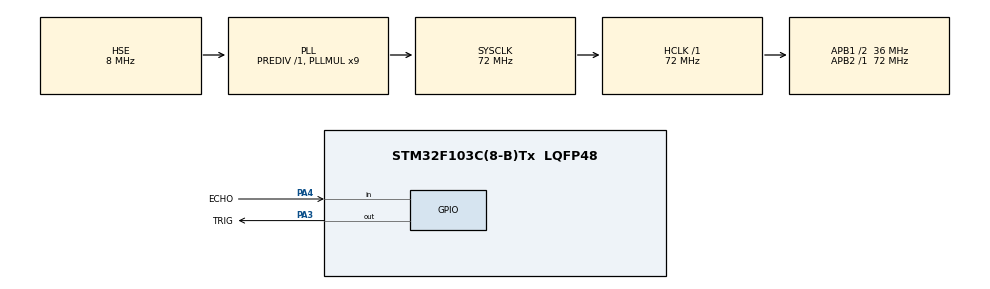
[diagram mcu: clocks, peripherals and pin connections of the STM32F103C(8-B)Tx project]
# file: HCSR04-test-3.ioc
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Mcu.Family=STM32F1
RCC.PLLSourceVirtual=RCC_PLLSOURCE_HSE
PD1-OSC_OUT.Mode=HSE-External-Oscillator
NVIC.TIM1_UP_IRQn=true\:0\:0\:false\:false\:true\:false\:true
PD0-OSC_IN.Signal=RCC_OSC_IN
RCC.APB1CLKDivider=RCC_HCLK_DIV2
RCC.SYSCLKSource=RCC_SYSCLKSOURCE_PLLCLK
ProjectManager.StackSize=0x400
PD1-OSC_OUT.Signal=RCC_OSC_OUT
PA13.Signal=SYS_JTMS-SWDIO
ProjectManager.TargetToolchain=STM32CubeIDE
RCC.HCLKFreq_Value=72000000
RCC.APB2TimFreq_Value=72000000
RCC.USBFreq_Value=72000000
RCC.AHBFreq_Value=72000000
PD0-OSC_IN.Mode=HSE-External-Oscillator
board=custom
RCC.PLLMUL=RCC_PLL_MUL9
RCC.APB2Freq_Value=72000000
VP_TIM2_VS_ClockSourceINT.Mode=Internal
PA14.Mode=Serial_Wire
VP_SYS_VS_tim1.Mode=TIM1
PA13.Mode=Serial_Wire
Mcu.Name=STM32F103C(8-B)Tx
PA4.Signal=GPIO_Input
RCC.SYSCLKFreq_VALUE=72000000
Mcu.Package=LQFP48
TIM2.Prescaler=71
NVIC.TimeBase=TIM1_UP_IRQn
NVIC.TimeBaseIP=TIM1
PA14.Signal=SYS_JTCK-SWCLK
ProjectManager.HeapSize=0x200
NVIC.PriorityGroup=NVIC_PRIORITYGROUP_4
RCC.APB1TimFreq_Value=72000000
RCC.APB1Freq_Value=36000000
PA4.GPIO_Label=ECHO
PA3.GPIO_Label=TRIG
PA3.Signal=GPIO_Output

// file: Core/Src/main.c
/* USER CODE BEGIN Header */
/**
  ******************************************************************************
  * @file           : main.c
  * @brief          : Main program body
  ******************************************************************************
  * @attention
  *
  * <h2><center>&copy; Copyright (c) 2024 STMicroelectronics.
  * All rights reserved.</center></h2>
  *
  * This software component is licensed by ST under BSD 3-Clause license,
  * the "License"; You may not use this file except in compliance with the
  * License. You may obtain a copy of the License at:
  *                        opensource.org/licenses/BSD-3-Clause
  *
  ******************************************************************************
  */
/* USER CODE END Header */
#include "main.h"

TIM_HandleTypeDef htim2;

/* USER CODE BEGIN PV */
uint32_t pMillis;
uint32_t val1 = 0;
uint32_t val2 = 0;
//uint16_t distance  = 0;
float distance  = 0;
char string[15];
/* USER CODE END PV */

void SystemClock_Config(void);
static void MX_GPIO_Init(void);
static void MX_TIM2_Init(void);

/* USER CODE BEGIN 0 */
int medir(void){
	  HAL_GPIO_WritePin(TRIG_GPIO_Port, TRIG_Pin, GPIO_PIN_SET);
	  __HAL_TIM_SET_COUNTER(&htim2, 0);
	   while (__HAL_TIM_GET_COUNTER (&htim2) < 10);  // wait for 10 us
	   HAL_GPIO_WritePin(TRIG_GPIO_Port, TRIG_Pin, GPIO_PIN_RESET);

	   pMillis = HAL_GetTick();
	   while (!(HAL_GPIO_ReadPin (ECHO_GPIO_Port, ECHO_Pin)) && pMillis + 10 >  HAL_GetTick());
	   val1 = __HAL_TIM_GET_COUNTER (&htim2);

	   pMillis = HAL_GetTick();
	   while ((HAL_GPIO_ReadPin (ECHO_GPIO_Port, ECHO_Pin)) && pMillis + 50 > HAL_GetTick());
	   val2 = __HAL_TIM_GET_COUNTER (&htim2);

	   distance = (val2-val1)* 0.036/2;
	   HAL_Delay(50);
}
/* USER CODE END 0 */

int main(void)
{

  /* MCU Configuration--------------------------------------------------------*/

  /* Reset of all peripherals, Initializes the Flash interface and the Systick. */
  HAL_Init();

  /* Configure the system clock */
  SystemClock_Config();

  /* Initialize all configured peripherals */
  MX_GPIO_Init();
  MX_TIM2_Init();
  /* USER CODE BEGIN 2 */
  HAL_TIM_Base_Start(&htim2);
  HAL_GPIO_WritePin(TRIG_GPIO_Port, TRIG_Pin, GPIO_PIN_RESET);
  /* USER CODE END 2 */

  /* Infinite loop */
  while (1)
  {
medir();
  }
}

void SystemClock_Config(void)
{
  RCC_OscInitTypeDef RCC_OscInitStruct = {0};
  RCC_ClkInitTypeDef RCC_ClkInitStruct = {0};

  /** Initializes the RCC Oscillators according to the specified parameters
  * in the RCC_OscInitTypeDef structure.
  */
  RCC_OscInitStruct.OscillatorType = RCC_OSCILLATORTYPE_HSE;
  RCC_OscInitStruct.HSEState = RCC_HSE_ON;
  RCC_OscInitStruct.HSEPredivValue = RCC_HSE_PREDIV_DIV1;
  RCC_OscInitStruct.HSIState = RCC_HSI_ON;
  RCC_OscInitStruct.PLL.PLLState = RCC_PLL_ON;
  RCC_OscInitStruct.PLL.PLLSource = RCC_PLLSOURCE_HSE;
  RCC_OscInitStruct.PLL.PLLMUL = RCC_PLL_MUL9;
  if (HAL_RCC_OscConfig(&RCC_OscInitStruct) != HAL_OK)
  {
    Error_Handler();
  }
  /** Initializes the CPU, AHB and APB buses clocks
  */
  RCC_ClkInitStruct.ClockType = RCC_CLOCKTYPE_HCLK|RCC_CLOCKTYPE_SYSCLK
                              |RCC_CLOCKTYPE_PCLK1|RCC_CLOCKTYPE_PCLK2;
  RCC_ClkInitStruct.SYSCLKSource = RCC_SYSCLKSOURCE_PLLCLK;
  RCC_ClkInitStruct.AHBCLKDivider = RCC_SYSCLK_DIV1;
  RCC_ClkInitStruct.APB1CLKDivider = RCC_HCLK_DIV2;
  RCC_ClkInitStruct.APB2CLKDivider = RCC_HCLK_DIV1;

  if (HAL_RCC_ClockConfig(&RCC_ClkInitStruct, FLASH_LATENCY_2) != HAL_OK)
  {
    Error_Handler();
  }
}

static void MX_TIM2_Init(void)
{

  TIM_ClockConfigTypeDef sClockSourceConfig = {0};
  TIM_MasterConfigTypeDef sMasterConfig = {0};

  htim2.Instance = TIM2;
  htim2.Init.Prescaler = 71;
  htim2.Init.CounterMode = TIM_COUNTERMODE_UP;
  htim2.Init.Period = 65535;
  htim2.Init.ClockDivision = TIM_CLOCKDIVISION_DIV1;
  htim2.Init.AutoReloadPreload = TIM_AUTORELOAD_PRELOAD_DISABLE;
  if (HAL_TIM_Base_Init(&htim2) != HAL_OK)
  {
    Error_Handler();
  }
  sClockSourceConfig.ClockSource = TIM_CLOCKSOURCE_INTERNAL;
  if (HAL_TIM_ConfigClockSource(&htim2, &sClockSourceConfig) != HAL_OK)
  {
    Error_Handler();
  }
  sMasterConfig.MasterOutputTrigger = TIM_TRGO_RESET;
  sMasterConfig.MasterSlaveMode = TIM_MASTERSLAVEMODE_DISABLE;
  if (HAL_TIMEx_MasterConfigSynchronization(&htim2, &sMasterConfig) != HAL_OK)
  {
    Error_Handler();
  }

}

static void MX_GPIO_Init(void)
{
  GPIO_InitTypeDef GPIO_InitStruct = {0};

  /* GPIO Ports Clock Enable */
  __HAL_RCC_GPIOD_CLK_ENABLE();
  __HAL_RCC_GPIOA_CLK_ENABLE();

  /*Configure GPIO pin Output Level */
  HAL_GPIO_WritePin(TRIG_GPIO_Port, TRIG_Pin, GPIO_PIN_RESET);

  /*Configure GPIO pin : TRIG_Pin */
  GPIO_InitStruct.Pin = TRIG_Pin;
  GPIO_InitStruct.Mode = GPIO_MODE_OUTPUT_PP;
  GPIO_InitStruct.Pull = GPIO_NOPULL;
  GPIO_InitStruct.Speed = GPIO_SPEED_FREQ_LOW;
  HAL_GPIO_Init(TRIG_GPIO_Port, &GPIO_InitStruct);

  /*Configure GPIO pin : ECHO_Pin */
  GPIO_InitStruct.Pin = ECHO_Pin;
  GPIO_InitStruct.Mode = GPIO_MODE_INPUT;
  GPIO_InitStruct.Pull = GPIO_NOPULL;
  HAL_GPIO_Init(ECHO_GPIO_Port, &GPIO_InitStruct);

}

 /**
  * @brief  Period elapsed callback in non blocking mode
  * @note   This function is called  when TIM1 interrupt took place, inside
  * HAL_TIM_IRQHandler(). It makes a direct call to HAL_IncTick() to increment
  * a global variable "uwTick" used as application time base.
  * @param  htim : TIM handle
  * @retval None
  */
void HAL_TIM_PeriodElapsedCallback(TIM_HandleTypeDef *htim)
{
  if (htim->Instance == TIM1) {
    HAL_IncTick();
  }
}

void Error_Handler(void)
{
  __disable_irq();
  while (1)
  {
  }
}

/************************ (C) COPYRIGHT STMicroelectronics *****END OF FILE****/
